AUTOSAR XML (schema 4-2-2)
package /ComponentTypes
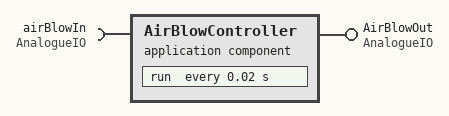
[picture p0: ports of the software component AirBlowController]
  application sw component type AirBlowController
    require port airBlowIn: nonqueued-receiver-com-spec{data-element=speed, init-value=0}, required-interface=AnalogueIO
    provide port AirBlowOut: nonqueued-sender-com-spec=speed, provided-interface=AnalogueIO
    behavior AirBlowController_InternalBehavior: data-type-mapping=speedMapSet
      data received event DRT_run_airBlowIn_speed: start-on-event=run, data=airBlowIn.speed
      timing event TMT_run: start-on-event=run, period=0.02
      runnable run
        data-receive-point-by-arguments:
          access REC_airBlowIn_speed: accessed-variable=airBlowIn.speed
        data-send-points:
          access SEND_AirBlowOut_speed: accessed-variable=AirBlowOut.speed
  swc implementation AirBlowController_Implementation: behavior=AirBlowController_InternalBehavior
